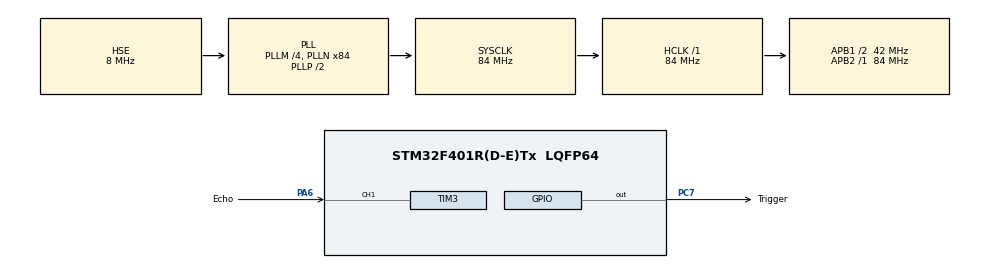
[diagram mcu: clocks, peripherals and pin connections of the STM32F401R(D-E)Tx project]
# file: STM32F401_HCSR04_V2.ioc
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Mcu.Family=STM32F4
Mcu.Name=STM32F401R(D-E)Tx
Mcu.Package=LQFP64
NVIC.PriorityGroup=NVIC_PRIORITYGROUP_4
PA13.Mode=Serial_Wire
PA13.Signal=SYS_JTMS-SWDIO
PA14.Mode=Serial_Wire
PA14.Signal=SYS_JTCK-SWCLK
PA6.GPIO_Label=Echo
PA6.Signal=S_TIM3_CH1
PC7.GPIO_Label=Trigger
PC7.Signal=GPIO_Output
PH0\ -\ OSC_IN.Mode=HSE-External-Oscillator
PH0\ -\ OSC_IN.Signal=RCC_OSC_IN
PH1\ -\ OSC_OUT.Mode=HSE-External-Oscillator
PH1\ -\ OSC_OUT.Signal=RCC_OSC_OUT
ProjectManager.HeapSize=0x200
ProjectManager.StackSize=0x400
ProjectManager.TargetToolchain=STM32CubeIDE
RCC.48MHZClocksFreq_Value=42000000
RCC.AHBFreq_Value=84000000
RCC.APB1CLKDivider=RCC_HCLK_DIV2
RCC.APB1Freq_Value=42000000
RCC.APB1TimFreq_Value=84000000
RCC.APB2Freq_Value=84000000
RCC.APB2TimFreq_Value=84000000
RCC.CortexFreq_Value=84000000
RCC.HCLKFreq_Value=84000000
RCC.HSE_VALUE=8000000
RCC.HSI_VALUE=16000000
RCC.LSE_VALUE=32768
RCC.PLLM=4
RCC.PLLN=84
RCC.PLLSourceVirtual=RCC_PLLSOURCE_HSE
RCC.SYSCLKFreq_VALUE=84000000
RCC.SYSCLKSource=RCC_SYSCLKSOURCE_PLLCLK
RCC.VCOOutputFreq_Value=168000000
SH.S_TIM3_CH1.0=TIM3_CH1,Input_Capture1_from_TI1
TIM3.Channel-Input_Capture1_from_TI1=TIM_CHANNEL_1
board=custom

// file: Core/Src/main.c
/* USER CODE BEGIN Header */
/**
  ******************************************************************************
  * @file           : main.c
  * @brief          : Main program body
  ******************************************************************************
  * @attention
  *
  * Copyright (c) 2023 STMicroelectronics.
  * All rights reserved.
  *
  * This software is licensed under terms that can be found in the LICENSE file
  * in the root directory of this software component.
  * If no LICENSE file comes with this software, it is provided AS-IS.
  *
  ******************************************************************************
  */
/* USER CODE END Header */
#include "main.h"

TIM_HandleTypeDef htim3;

/* USER CODE BEGIN PV */

uint32_t sensor_time; 						// Sensor suresini hesaplamak icin degisken tanimliyoruz
float distance =0; 						    // Mesafe bilgisini tutmak icin bir degisken tanimliyoruz

/* USER CODE END PV */

void SystemClock_Config(void);
static void MX_GPIO_Init(void);
static void MX_TIM3_Init(void);
/* USER CODE BEGIN PFP */

void delay(uint16_t time) 				    // Mikro saniye elde edebilmek icin bir fonksiyon
{

	__HAL_TIM_SET_COUNTER(&htim3,0);
 while(__HAL_TIM_GET_COUNTER(&htim3) < time );
 }

#define Trigger_Pin GPIO_PIN_7
#define Echo_Pin GPIO_PIN_6

float Sensor_Read() 				    	// Sensor suresini hesaplamak icin bir fonksiyon
{
	uint32_t time =0;

	HAL_GPIO_WritePin(Trigger_GPIO_Port, Trigger_Pin, GPIO_PIN_RESET);
	HAL_Delay(2);
	HAL_GPIO_WritePin(Trigger_GPIO_Port, Trigger_Pin, GPIO_PIN_SET);
	HAL_Delay(10);
	HAL_GPIO_WritePin(Trigger_GPIO_Port, Trigger_Pin, GPIO_PIN_RESET);

	while(!HAL_GPIO_ReadPin(Echo_GPIO_Port, Echo_Pin));
	while(HAL_GPIO_ReadPin(Echo_GPIO_Port, Echo_Pin))
	{
		time++;
		delay(1);

	}
	return time;
}

/* USER CODE END PFP */

int main(void)
{

  /* MCU Configuration--------------------------------------------------------*/

  /* Reset of all peripherals, Initializes the Flash interface and the Systick. */
  HAL_Init();

  /* Configure the system clock */
  SystemClock_Config();

  /* Initialize all configured peripherals */
  MX_GPIO_Init();
  MX_TIM3_Init();
  /* USER CODE BEGIN 2 */
  HAL_TIM_Base_Start(&htim3); 						// TIMER'i baslatiyoruz

  /* USER CODE END 2 */

  /* Infinite loop */
  /* USER CODE BEGIN WHILE */
  while (1)
  {
	  sensor_time = Sensor_Read(); 					// sensorede gecen sureyi aliyoruz
	  HAL_Delay(200); 								// 200 ms bekliyoruz
	  distance  = sensor_time * .034/2; 			// mesafeyi hesapliyoruz

    /* USER CODE END WHILE */

  }
}

void SystemClock_Config(void)
{
  RCC_OscInitTypeDef RCC_OscInitStruct = {0};
  RCC_ClkInitTypeDef RCC_ClkInitStruct = {0};

  /** Configure the main internal regulator output voltage
  */
  __HAL_RCC_PWR_CLK_ENABLE();
  __HAL_PWR_VOLTAGESCALING_CONFIG(PWR_REGULATOR_VOLTAGE_SCALE2);

  /** Initializes the RCC Oscillators according to the specified parameters
  * in the RCC_OscInitTypeDef structure.
  */
  RCC_OscInitStruct.OscillatorType = RCC_OSCILLATORTYPE_HSE;
  RCC_OscInitStruct.HSEState = RCC_HSE_ON;
  RCC_OscInitStruct.PLL.PLLState = RCC_PLL_ON;
  RCC_OscInitStruct.PLL.PLLSource = RCC_PLLSOURCE_HSE;
  RCC_OscInitStruct.PLL.PLLM = 4;
  RCC_OscInitStruct.PLL.PLLN = 84;
  RCC_OscInitStruct.PLL.PLLP = RCC_PLLP_DIV2;
  RCC_OscInitStruct.PLL.PLLQ = 4;
  if (HAL_RCC_OscConfig(&RCC_OscInitStruct) != HAL_OK)
  {
    Error_Handler();
  }

  /** Initializes the CPU, AHB and APB buses clocks
  */
  RCC_ClkInitStruct.ClockType = RCC_CLOCKTYPE_HCLK|RCC_CLOCKTYPE_SYSCLK
                              |RCC_CLOCKTYPE_PCLK1|RCC_CLOCKTYPE_PCLK2;
  RCC_ClkInitStruct.SYSCLKSource = RCC_SYSCLKSOURCE_PLLCLK;
  RCC_ClkInitStruct.AHBCLKDivider = RCC_SYSCLK_DIV1;
  RCC_ClkInitStruct.APB1CLKDivider = RCC_HCLK_DIV2;
  RCC_ClkInitStruct.APB2CLKDivider = RCC_HCLK_DIV1;

  if (HAL_RCC_ClockConfig(&RCC_ClkInitStruct, FLASH_LATENCY_2) != HAL_OK)
  {
    Error_Handler();
  }
}

static void MX_TIM3_Init(void)
{

  TIM_MasterConfigTypeDef sMasterConfig = {0};
  TIM_IC_InitTypeDef sConfigIC = {0};

  htim3.Instance = TIM3;
  htim3.Init.Prescaler = 0;
  htim3.Init.CounterMode = TIM_COUNTERMODE_UP;
  htim3.Init.Period = 65535;
  htim3.Init.ClockDivision = TIM_CLOCKDIVISION_DIV1;
  htim3.Init.AutoReloadPreload = TIM_AUTORELOAD_PRELOAD_DISABLE;
  if (HAL_TIM_IC_Init(&htim3) != HAL_OK)
  {
    Error_Handler();
  }
  sMasterConfig.MasterOutputTrigger = TIM_TRGO_RESET;
  sMasterConfig.MasterSlaveMode = TIM_MASTERSLAVEMODE_DISABLE;
  if (HAL_TIMEx_MasterConfigSynchronization(&htim3, &sMasterConfig) != HAL_OK)
  {
    Error_Handler();
  }
  sConfigIC.ICPolarity = TIM_INPUTCHANNELPOLARITY_RISING;
  sConfigIC.ICSelection = TIM_ICSELECTION_DIRECTTI;
  sConfigIC.ICPrescaler = TIM_ICPSC_DIV1;
  sConfigIC.ICFilter = 0;
  if (HAL_TIM_IC_ConfigChannel(&htim3, &sConfigIC, TIM_CHANNEL_1) != HAL_OK)
  {
    Error_Handler();
  }

}

static void MX_GPIO_Init(void)
{
  GPIO_InitTypeDef GPIO_InitStruct = {0};

  /* GPIO Ports Clock Enable */
  __HAL_RCC_GPIOH_CLK_ENABLE();
  __HAL_RCC_GPIOA_CLK_ENABLE();
  __HAL_RCC_GPIOC_CLK_ENABLE();

  /*Configure GPIO pin Output Level */
  HAL_GPIO_WritePin(Trigger_GPIO_Port, Trigger_Pin, GPIO_PIN_RESET);

  /*Configure GPIO pin : Trigger_Pin */
  GPIO_InitStruct.Pin = Trigger_Pin;
  GPIO_InitStruct.Mode = GPIO_MODE_OUTPUT_PP;
  GPIO_InitStruct.Pull = GPIO_NOPULL;
  GPIO_InitStruct.Speed = GPIO_SPEED_FREQ_LOW;
  HAL_GPIO_Init(Trigger_GPIO_Port, &GPIO_InitStruct);

}

void Error_Handler(void)
{
  __disable_irq();
  while (1)
  {
  }
}
